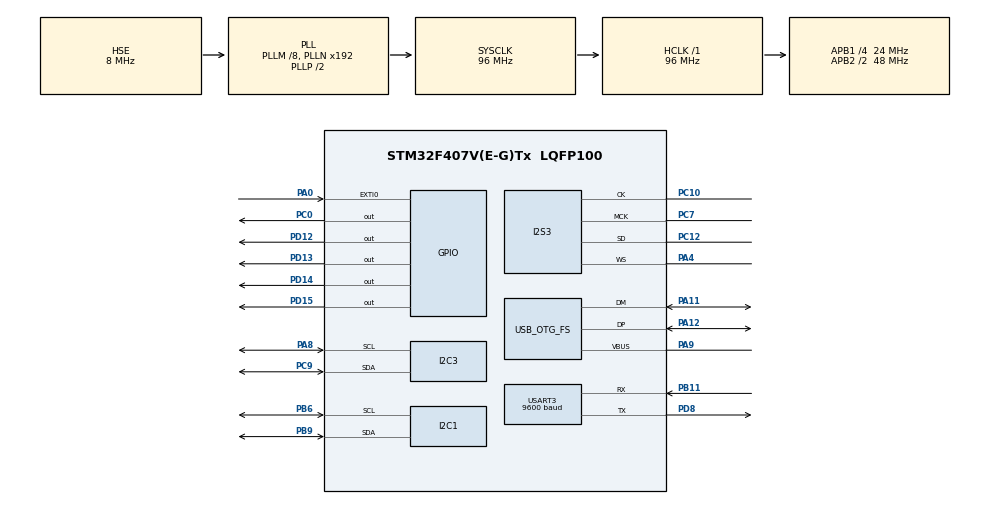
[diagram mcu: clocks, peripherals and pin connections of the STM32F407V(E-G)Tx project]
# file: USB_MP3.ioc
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Dma.Request0=SPI3_TX
Dma.Request1=USART3_RX
Dma.Request2=USART3_TX
Dma.SPI3_TX.0.Direction=DMA_MEMORY_TO_PERIPH
Dma.SPI3_TX.0.FIFOMode=DMA_FIFOMODE_ENABLE
Dma.SPI3_TX.0.FIFOThreshold=DMA_FIFO_THRESHOLD_FULL
Dma.SPI3_TX.0.Instance=DMA1_Stream5
Dma.SPI3_TX.0.MemBurst=DMA_MBURST_SINGLE
Dma.SPI3_TX.0.MemDataAlignment=DMA_MDATAALIGN_HALFWORD
Dma.SPI3_TX.0.MemInc=DMA_MINC_ENABLE
Dma.SPI3_TX.0.Mode=DMA_CIRCULAR
Dma.SPI3_TX.0.PeriphBurst=DMA_PBURST_SINGLE
Dma.SPI3_TX.0.PeriphDataAlignment=DMA_PDATAALIGN_HALFWORD
Dma.SPI3_TX.0.PeriphInc=DMA_PINC_DISABLE
Dma.SPI3_TX.0.Priority=DMA_PRIORITY_HIGH
Dma.USART3_RX.1.Direction=DMA_PERIPH_TO_MEMORY
Dma.USART3_RX.1.FIFOMode=DMA_FIFOMODE_DISABLE
Dma.USART3_RX.1.Instance=DMA1_Stream1
Dma.USART3_RX.1.MemDataAlignment=DMA_MDATAALIGN_BYTE
Dma.USART3_RX.1.MemInc=DMA_MINC_ENABLE
Dma.USART3_RX.1.Mode=DMA_NORMAL
Dma.USART3_RX.1.PeriphDataAlignment=DMA_PDATAALIGN_BYTE
Dma.USART3_RX.1.PeriphInc=DMA_PINC_DISABLE
Dma.USART3_RX.1.Priority=DMA_PRIORITY_LOW
Dma.USART3_TX.2.Direction=DMA_MEMORY_TO_PERIPH
Dma.USART3_TX.2.FIFOMode=DMA_FIFOMODE_DISABLE
Dma.USART3_TX.2.Instance=DMA1_Stream3
Dma.USART3_TX.2.MemDataAlignment=DMA_MDATAALIGN_BYTE
Dma.USART3_TX.2.MemInc=DMA_MINC_ENABLE
Dma.USART3_TX.2.Mode=DMA_NORMAL
Dma.USART3_TX.2.PeriphDataAlignment=DMA_PDATAALIGN_BYTE
Dma.USART3_TX.2.PeriphInc=DMA_PINC_DISABLE
Dma.USART3_TX.2.Priority=DMA_PRIORITY_LOW
FATFS._USE_LFN=1
I2S3.AudioFreq=I2S_AUDIOFREQ_44K
I2S3.ErrorAudioFreq=1.45 %
I2S3.FullDuplexMode=I2S_FULLDUPLEXMODE_DISABLE
I2S3.Instance=SPI$Index
I2S3.RealAudioFreq=44.642 KHz
I2S3.VirtualMode=I2S_MODE_MASTER
Mcu.Family=STM32F4
Mcu.Name=STM32F407V(E-G)Tx
Mcu.Package=LQFP100
NVIC.DMA1_Stream1_IRQn=true\:7\:0\:false\:false\:true\:false\:true\:true
NVIC.DMA1_Stream3_IRQn=true\:7\:0\:false\:false\:true\:false\:true\:true
NVIC.DMA1_Stream5_IRQn=true\:6\:0\:false\:false\:true\:false\:true\:true
NVIC.EXTI0_IRQn=true\:7\:0\:false\:false\:true\:true\:true\:true
NVIC.I2C3_ER_IRQn=true\:8\:0\:false\:false\:true\:true\:true\:true
NVIC.I2C3_EV_IRQn=true\:8\:0\:false\:false\:true\:true\:true\:true
NVIC.OTG_FS_IRQn=true\:6\:0\:false\:false\:true\:false\:true\:true
NVIC.PriorityGroup=NVIC_PRIORITYGROUP_4
NVIC.USART3_IRQn=true\:7\:0\:false\:false\:true\:true\:true\:true
PA0-WKUP.GPIO_PuPd=GPIO_PULLDOWN
PA0-WKUP.Signal=GPXTI0
PA11.Mode=Host_Only
PA11.Signal=USB_OTG_FS_DM
PA12.Mode=Host_Only
PA12.Signal=USB_OTG_FS_DP
PA4.Mode=Half_Duplex_Master
PA4.Signal=I2S3_WS
PA8.GPIO_Pu=GPIO_PULLUP
PA8.Mode=I2C
PA8.Signal=I2C3_SCL
PA9.Mode=Activate_VBUS
PA9.Signal=USB_OTG_FS_VBUS
PB11.Mode=Asynchronous
PB11.Signal=USART3_RX
PB6.GPIO_Pu=GPIO_PULLUP
PB6.Mode=I2C
PB6.Signal=I2C1_SCL
PB9.GPIO_Pu=GPIO_PULLUP
PB9.Mode=I2C
PB9.Signal=I2C1_SDA
PC0.Signal=GPIO_Output
PC10.Mode=Half_Duplex_Master
PC10.Signal=I2S3_CK
PC12.Mode=Half_Duplex_Master
PC12.Signal=I2S3_SD
PC7.Mode=Master_Clock_Activated
PC7.Signal=I2S3_MCK
PC9.GPIO_Pu=GPIO_PULLUP
PC9.Mode=I2C
PC9.Signal=I2C3_SDA
PD12.Signal=GPIO_Output
PD13.Signal=GPIO_Output
PD14.Signal=GPIO_Output
PD15.Signal=GPIO_Output
PD8.Mode=Asynchronous
PD8.Signal=USART3_TX
PH0-OSC_IN.Mode=HSE-External-Oscillator
PH0-OSC_IN.Signal=RCC_OSC_IN
PH1-OSC_OUT.Mode=HSE-External-Oscillator
PH1-OSC_OUT.Signal=RCC_OSC_OUT
ProjectManager.HeapSize=0x200
ProjectManager.StackSize=0x400
ProjectManager.TargetToolchain=STM32CubeIDE
RCC.48MHZClocksFreq_Value=48000000
RCC.AHBFreq_Value=96000000
RCC.APB1CLKDivider=RCC_HCLK_DIV4
RCC.APB1Freq_Value=24000000
RCC.APB1TimFreq_Value=48000000
RCC.APB2CLKDivider=RCC_HCLK_DIV2
RCC.APB2Freq_Value=48000000
RCC.APB2TimFreq_Value=96000000
RCC.CortexFreq_Value=96000000
RCC.HCLKFreq_Value=96000000
RCC.HSE_VALUE=8000000
RCC.HSI_VALUE=16000000
RCC.LSE_VALUE=32768
RCC.PLLI2SN=320
RCC.PLLM=8
RCC.SYSCLKFreq_VALUE=96000000
RCC.SYSCLKSource=RCC_SYSCLKSOURCE_PLLCLK
RCC.VCOOutputFreq_Value=192000000
USART3.BaudRate=9600
USART3.VirtualMode=VM_ASYNC
USB_HOST.BSP.number=1
USB_HOST.USBH_HandleTypeDef-MSC_FS=hUsbHostFS
USB_HOST.VirtualModeFS=Msc
USB_HOST0.BSP.STBoard=false
USB_HOST0.BSP.api=Unknown
USB_HOST0.BSP.instance=PC0
USB_HOST0.BSP.ip=GPIO
USB_HOST0.BSP.mode=Output
USB_HOST0.BSP.name=Drive_VBUS_FS
USB_HOST0.BSP.solution=PC0
USB_OTG_FS.VirtualMode=Host_Only
USB_OTG_FS.phy_itface=HCD_PHY_EMBEDDED
VP_FATFS_VS_USB.Mode=USB
VP_USB_HOST_VS_USB_HOST_MSC_FS.Mode=MSC_FS
board=custom

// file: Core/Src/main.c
/* USER CODE BEGIN Header */
/**
 ******************************************************************************
 * @file           : main.c
 * @brief          : Main program body
 ******************************************************************************
 * @attention
 *
 * Copyright (c) 2024 STMicroelectronics.
 * All rights reserved.
 *
 * This software is licensed under terms that can be found in the LICENSE file
 * in the root directory of this software component.
 * If no LICENSE file comes with this software, it is provided AS-IS.
 *
 ******************************************************************************
 */
/* USER CODE END Header */
#include "main.h"

#include "fatfs.h"
#include "usb_host.h"

/* USER CODE BEGIN Includes */
#include "app_main.h"
/* USER CODE END Includes */

I2C_HandleTypeDef hi2c1;
I2C_HandleTypeDef hi2c3;

I2S_HandleTypeDef hi2s3;
DMA_HandleTypeDef hdma_spi3_tx;

UART_HandleTypeDef huart3;
DMA_HandleTypeDef hdma_usart3_rx;
DMA_HandleTypeDef hdma_usart3_tx;

void SystemClock_Config(void);
static void MX_GPIO_Init(void);
static void MX_DMA_Init(void);
static void MX_I2C1_Init(void);
static void MX_I2S3_Init(void);
static void MX_I2C3_Init(void);
static void MX_USART3_UART_Init(void);
void MX_USB_HOST_Process(void);

int main(void) {

  /* MCU Configuration--------------------------------------------------------*/

  /* Reset of all peripherals, Initializes the Flash interface and the Systick.
   */
  HAL_Init();

  /* Configure the system clock */
  SystemClock_Config();

  /* Initialize all configured peripherals */
  MX_GPIO_Init();
  MX_DMA_Init();
  MX_I2C1_Init();
  MX_I2S3_Init();
  MX_FATFS_Init();
  MX_USB_HOST_Init();
  MX_I2C3_Init();
  MX_USART3_UART_Init();
  /* USER CODE BEGIN 2 */
  app_main_start(&huart3, &hi2c3);
  /* USER CODE END 2 */

  /* Infinite loop */
  while (1) {

    /* USER CODE BEGIN 3 */
    __WFI();
  }
  /* USER CODE END 3 */
}

void SystemClock_Config(void) {
  RCC_OscInitTypeDef RCC_OscInitStruct = {0};
  RCC_ClkInitTypeDef RCC_ClkInitStruct = {0};

  /** Configure the main internal regulator output voltage
   */
  __HAL_RCC_PWR_CLK_ENABLE();
  __HAL_PWR_VOLTAGESCALING_CONFIG(PWR_REGULATOR_VOLTAGE_SCALE1);

  /** Initializes the RCC Oscillators according to the specified parameters
   * in the RCC_OscInitTypeDef structure.
   */
  RCC_OscInitStruct.OscillatorType = RCC_OSCILLATORTYPE_HSE;
  RCC_OscInitStruct.HSEState = RCC_HSE_ON;
  RCC_OscInitStruct.PLL.PLLState = RCC_PLL_ON;
  RCC_OscInitStruct.PLL.PLLSource = RCC_PLLSOURCE_HSE;
  RCC_OscInitStruct.PLL.PLLM = 8;
  RCC_OscInitStruct.PLL.PLLN = 192;
  RCC_OscInitStruct.PLL.PLLP = RCC_PLLP_DIV2;
  RCC_OscInitStruct.PLL.PLLQ = 4;
  if (HAL_RCC_OscConfig(&RCC_OscInitStruct) != HAL_OK) {
    Error_Handler();
  }

  /** Initializes the CPU, AHB and APB buses clocks
   */
  RCC_ClkInitStruct.ClockType = RCC_CLOCKTYPE_HCLK | RCC_CLOCKTYPE_SYSCLK |
                                RCC_CLOCKTYPE_PCLK1 | RCC_CLOCKTYPE_PCLK2;
  RCC_ClkInitStruct.SYSCLKSource = RCC_SYSCLKSOURCE_PLLCLK;
  RCC_ClkInitStruct.AHBCLKDivider = RCC_SYSCLK_DIV1;
  RCC_ClkInitStruct.APB1CLKDivider = RCC_HCLK_DIV4;
  RCC_ClkInitStruct.APB2CLKDivider = RCC_HCLK_DIV2;

  if (HAL_RCC_ClockConfig(&RCC_ClkInitStruct, FLASH_LATENCY_3) != HAL_OK) {
    Error_Handler();
  }
}

static void MX_I2C1_Init(void) {

  hi2c1.Instance = I2C1;
  hi2c1.Init.ClockSpeed = 100000;
  hi2c1.Init.DutyCycle = I2C_DUTYCYCLE_2;
  hi2c1.Init.OwnAddress1 = 0;
  hi2c1.Init.AddressingMode = I2C_ADDRESSINGMODE_7BIT;
  hi2c1.Init.DualAddressMode = I2C_DUALADDRESS_DISABLE;
  hi2c1.Init.OwnAddress2 = 0;
  hi2c1.Init.GeneralCallMode = I2C_GENERALCALL_DISABLE;
  hi2c1.Init.NoStretchMode = I2C_NOSTRETCH_DISABLE;
  if (HAL_I2C_Init(&hi2c1) != HAL_OK) {
    Error_Handler();
  }
}

static void MX_I2C3_Init(void) {

  hi2c3.Instance = I2C3;
  hi2c3.Init.ClockSpeed = 100000;
  hi2c3.Init.DutyCycle = I2C_DUTYCYCLE_2;
  hi2c3.Init.OwnAddress1 = 0;
  hi2c3.Init.AddressingMode = I2C_ADDRESSINGMODE_7BIT;
  hi2c3.Init.DualAddressMode = I2C_DUALADDRESS_DISABLE;
  hi2c3.Init.OwnAddress2 = 0;
  hi2c3.Init.GeneralCallMode = I2C_GENERALCALL_DISABLE;
  hi2c3.Init.NoStretchMode = I2C_NOSTRETCH_DISABLE;
  if (HAL_I2C_Init(&hi2c3) != HAL_OK) {
    Error_Handler();
  }
}

static void MX_I2S3_Init(void) {

  hi2s3.Instance = SPI3;
  hi2s3.Init.Mode = I2S_MODE_MASTER_TX;
  hi2s3.Init.Standard = I2S_STANDARD_PHILIPS;
  hi2s3.Init.DataFormat = I2S_DATAFORMAT_16B;
  hi2s3.Init.MCLKOutput = I2S_MCLKOUTPUT_ENABLE;
  hi2s3.Init.AudioFreq = I2S_AUDIOFREQ_44K;
  hi2s3.Init.CPOL = I2S_CPOL_LOW;
  hi2s3.Init.ClockSource = I2S_CLOCK_PLL;
  hi2s3.Init.FullDuplexMode = I2S_FULLDUPLEXMODE_DISABLE;
  if (HAL_I2S_Init(&hi2s3) != HAL_OK) {
    Error_Handler();
  }
}

static void MX_USART3_UART_Init(void) {

  huart3.Instance = USART3;
  huart3.Init.BaudRate = 9600;
  huart3.Init.WordLength = UART_WORDLENGTH_8B;
  huart3.Init.StopBits = UART_STOPBITS_1;
  huart3.Init.Parity = UART_PARITY_NONE;
  huart3.Init.Mode = UART_MODE_TX_RX;
  huart3.Init.HwFlowCtl = UART_HWCONTROL_NONE;
  huart3.Init.OverSampling = UART_OVERSAMPLING_16;
  if (HAL_UART_Init(&huart3) != HAL_OK) {
    Error_Handler();
  }
}

static void MX_DMA_Init(void) {
  /* DMA controller clock enable */
  __HAL_RCC_DMA1_CLK_ENABLE();

  /* DMA interrupt init */
  /* DMA1_Stream1_IRQn interrupt configuration */
  HAL_NVIC_SetPriority(DMA1_Stream1_IRQn, 7, 0);
  HAL_NVIC_EnableIRQ(DMA1_Stream1_IRQn);
  /* DMA1_Stream3_IRQn interrupt configuration */
  HAL_NVIC_SetPriority(DMA1_Stream3_IRQn, 7, 0);
  HAL_NVIC_EnableIRQ(DMA1_Stream3_IRQn);
  /* DMA1_Stream5_IRQn interrupt configuration */
  HAL_NVIC_SetPriority(DMA1_Stream5_IRQn, 6, 0);
  HAL_NVIC_EnableIRQ(DMA1_Stream5_IRQn);
}

static void MX_GPIO_Init(void) {
  GPIO_InitTypeDef GPIO_InitStruct = {0};

  /* GPIO Ports Clock Enable */
  __HAL_RCC_GPIOH_CLK_ENABLE();
  __HAL_RCC_GPIOC_CLK_ENABLE();
  __HAL_RCC_GPIOA_CLK_ENABLE();
  __HAL_RCC_GPIOB_CLK_ENABLE();
  __HAL_RCC_GPIOD_CLK_ENABLE();

  /*Configure GPIO pin Output Level */
  HAL_GPIO_WritePin(GPIOC, GPIO_PIN_0, GPIO_PIN_RESET);

  /*Configure GPIO pin Output Level */
  HAL_GPIO_WritePin(GPIOD,
                    GPIO_PIN_12 | GPIO_PIN_13 | GPIO_PIN_14 | GPIO_PIN_15,
                    GPIO_PIN_RESET);

  /*Configure GPIO pin : PC0 */
  GPIO_InitStruct.Pin = GPIO_PIN_0;
  GPIO_InitStruct.Mode = GPIO_MODE_OUTPUT_PP;
  GPIO_InitStruct.Pull = GPIO_NOPULL;
  GPIO_InitStruct.Speed = GPIO_SPEED_FREQ_LOW;
  HAL_GPIO_Init(GPIOC, &GPIO_InitStruct);

  /*Configure GPIO pin : PA0 */
  GPIO_InitStruct.Pin = GPIO_PIN_0;
  GPIO_InitStruct.Mode = GPIO_MODE_IT_RISING;
  GPIO_InitStruct.Pull = GPIO_PULLDOWN;
  HAL_GPIO_Init(GPIOA, &GPIO_InitStruct);

  /*Configure GPIO pins : PD12 PD13 PD14 PD15 */
  GPIO_InitStruct.Pin = GPIO_PIN_12 | GPIO_PIN_13 | GPIO_PIN_14 | GPIO_PIN_15;
  GPIO_InitStruct.Mode = GPIO_MODE_OUTPUT_PP;
  GPIO_InitStruct.Pull = GPIO_NOPULL;
  GPIO_InitStruct.Speed = GPIO_SPEED_FREQ_LOW;
  HAL_GPIO_Init(GPIOD, &GPIO_InitStruct);

  /* EXTI interrupt init*/
  HAL_NVIC_SetPriority(EXTI0_IRQn, 7, 0);
  HAL_NVIC_EnableIRQ(EXTI0_IRQn);
}

void Error_Handler(void) {
  /* USER CODE BEGIN Error_Handler_Debug */
  /* User can add his own implementation to report the HAL error return state
   */
  __disable_irq();
  while (1) {
  }
  /* USER CODE END Error_Handler_Debug */
}

#ifdef USE_FULL_ASSERT
/**
 * @brief  Reports the name of the source file and the source line number
 *         where the assert_param error has occurred.
 * @param  file: pointer to the source file name
 * @param  line: assert_param error line source number
 * @retval None
 */
void assert_failed(uint8_t *file, uint32_t line) {
  /* USER CODE BEGIN 6 */
  /* User can add his own implementation to report the file name and line
     number, ex: printf("Wrong parameters value: file %s on line %d\r\n",
     file, line) */
  /* USER CODE END 6 */
}
#endif /* USE_FULL_ASSERT */
